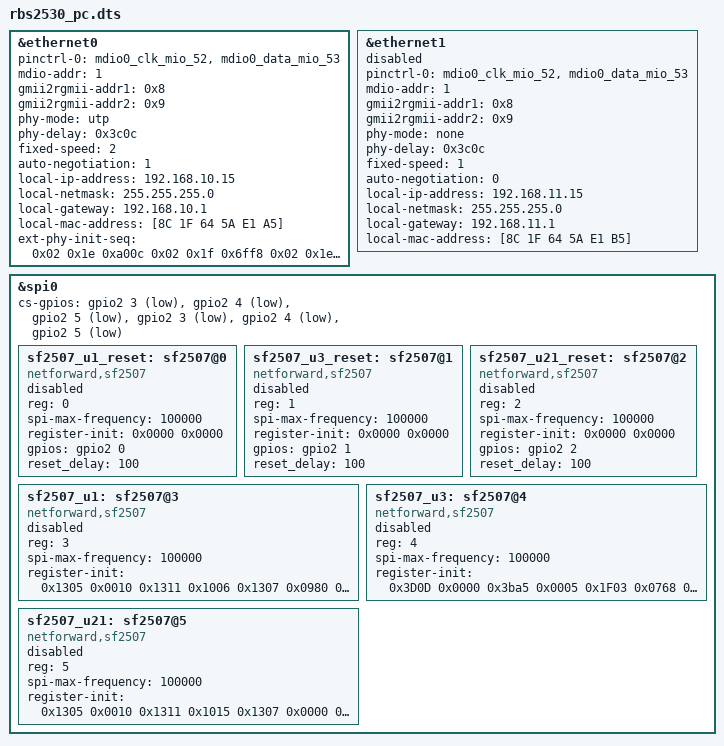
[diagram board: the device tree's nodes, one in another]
/*
 * Copyright (c) 2025 SYSFly Co.
 * SPDX-License-Identifier: Apache-2.0
 */

/dts-v1/;

#include <fmsh/rbs2530.dtsi>
#include <dt-bindings/gpio/gpio.h>

&ethernet0 {
	pinctrl-0 = <&mdio0_clk_mio_52>, <&mdio0_data_mio_53>;
	pinctrl-names = "default";
	mdio-addr = <1>;
	gmii2rgmii-addr1 = <0x8>;
	gmii2rgmii-addr2 = <0x9>;
	phy-mode = "utp";  /* fiber or utp */
	phy-delay = <0x3c0c>;
	fixed-speed = <2>;  /* 0:10M, 1:100M, 2:1000M */
	auto-negotiation = <1>;
	local-ip-address = "192.168.10.15";
	local-netmask = "255.255.255.0";
	local-gateway = "192.168.10.1";
	local-mac-address = [8C 1F 64 5A E1 A5];
	ext-phy-init-seq = <
		/* ---- PHY 2 ---- */
		0x02 0x1e 0xa00c
		0x02 0x1f 0x6ff8
		0x02 0x1e 0xa00d
		0x02 0x1f 0x6ff8
		0x02 0x1e 0xa00e
		0x02 0x1f 0x6ff8
		0xff 0xee 0x01
		0x02 0x00 0x9100
		0xff 0xee 0x0b

		/* ---- PHY 5 ---- */
		0x05 0x1e 0xa00c
		0x05 0x1f 0x6ff8
		0x05 0x1e 0xa00d
		0x05 0x1f 0x6ff8
		0x05 0x1e 0xa00e
		0x05 0x1f 0x6ff8
		0xff 0xee 0x01
		0x05 0x00 0x9100
		0xff 0xee 0x0b
	>;
	status = "okay";
};

&ethernet1 {
	pinctrl-0 = <&mdio0_clk_mio_52>, <&mdio0_data_mio_53>;
	pinctrl-names = "default";
	mdio-addr = <1>;
	gmii2rgmii-addr1 = <0x8>;
	gmii2rgmii-addr2 = <0x9>;
	phy-mode = "none";  /* fiber or utp or none */
	phy-delay = <0x3c0c>;
	/* This GMAC only supports forced 100Mbps mode */
	fixed-speed = <1>;
	/* auto-negotiation is disabled since speed is forced to 100Mbps */
	auto-negotiation = <0>;
	local-ip-address = "192.168.11.15";
	local-netmask = "255.255.255.0";
	local-gateway = "192.168.11.1";
	local-mac-address = [8C 1F 64 5A E1 B5];
	status = "disabled";
};

&spi0 {
	cs-gpios =
			<&gpio2 3 GPIO_ACTIVE_LOW>,
			<&gpio2 4 GPIO_ACTIVE_LOW>,
			<&gpio2 5 GPIO_ACTIVE_LOW>,
			<&gpio2 3 GPIO_ACTIVE_LOW>,
			<&gpio2 4 GPIO_ACTIVE_LOW>,
			<&gpio2 5 GPIO_ACTIVE_LOW>;

	sf2507_u1_reset: sf2507@0 {
		compatible = "netforward,sf2507";
		reg = <0>;
		status = "disabled";
		spi-max-frequency = <100000>;
		register-init = <
			0x0000 0x0000
		>;

		gpios = <&gpio2 0 0>;
		reset_delay = < 100 >;
	};

	sf2507_u3_reset: sf2507@1 {
		compatible = "netforward,sf2507";
		reg = <1>;
		status = "disabled";
		spi-max-frequency = <100000>;
		register-init = <
			0x0000 0x0000
		>;

		gpios = <&gpio2 1 0>;
		reset_delay = < 100 >;
	};

	sf2507_u21_reset: sf2507@2 {
		compatible = "netforward,sf2507";
		reg = <2>;
		status = "disabled";
		spi-max-frequency = <100000>;
		register-init = <
			0x0000 0x0000
		>;
		gpios = <&gpio2 2 0>;
		reset_delay = < 100 >;
	};

	sf2507_u1: sf2507@3 {
		compatible = "netforward,sf2507";
		reg = <3>;
		status = "disabled";
		spi-max-frequency = <100000>;
		register-init = <
			0x1305 0x0010
			0x1311 0x1006
			0x1307 0x0980
			0x3B0C 0x0003
			0x3EE0 0x0022
			0x3BA7 0x0005
			0x1F03 0x0768
			0x1F02 0x0052
			0x1F00 0x0003
			0x3BA8 0x0005
			0x1F03 0x0768
			0x1F02 0x0072
			0x1F00 0x0003
			0x3BA9 0x0005
			0x1F03 0x0768
			0x1F02 0x0092
			0x1F00 0x0003
			0x3BE4 0x0003
		>;
	};

	sf2507_u3: sf2507@4 {
		compatible = "netforward,sf2507";
		reg = <4>;
		status = "disabled";
		spi-max-frequency = <100000>;
		register-init = <
			0x3D0D 0x0000
			0x3ba5 0x0005
			0x1F03 0x0768
			0x1F02 0x12
			0x1F00 0x0003
			0x3ba6 0x0005
			0x1F03 0x0768
			0x1F02 0x32
			0x1F00 0x0003
			0x3ba7 0x0005
			0x1F03 0x0768
			0x1F02 0x52
			0x1F00 0x0003
			0x3ba8 0x0005
			0x1F03 0x0768
			0x1F02 0x72
			0x1F00 0x0003
		>;
	};

	sf2507_u21: sf2507@5 {
		compatible = "netforward,sf2507";
		reg = <5>;
		status = "disabled";
		spi-max-frequency = <100000>;
		register-init = <
			0x1305 0x0010
			0x1311 0x1015
			0x1307 0x0000
			0x3B0C 0x0007
			0x13C3 0x0001
			0x13C4 0x1006
			0x13C5 0x0980
			0x3B0D 0x0003
			0x3EE0 0x0022
			0x3D0D 0x0000
			0x3BA5 0x0005
			0x1F03 0x0768
			0x1F02 0x0012
			0x1F00 0x0003
			0x3BA6 0x0005
			0x1F03 0x0768
			0x1F02 0x0032
			0x1F00 0x0003
			0x3BA7 0x0005
			0x1F03 0x0768
			0x1F02 0x0052
			0x1F00 0x0003
			0x3BA8 0x0005
			0x1F03 0x0768
			0x1F02 0x0072
			0x1F00 0x0003
			0x3BA9 0x0005
			0x1F03 0x0768
			0x1F02 0x0092
			0x1F00 0x0003
			0x3BE4 0x0003
		>;
	};
};
